# MKW21Z4 register map
Vendor: Freescale Semiconductor, Inc.; Series: Kinetis_W; File version: 1.6
CPU: CM0PLUS r0p0, little endian, no MPU, no FPU, VTOR, 2 interrupt priority bits
Registers are 16-bit, read-write, no defined reset value unless marked. A register's access mark holds for its fields unless they carry their own. Offsets are from the block's base; [hi:lo] are bit positions; {n}, {i} and the like mark numbered series.

## TX_DIG_REGS — XCVR_TX_DIG
Base 0x4005C200
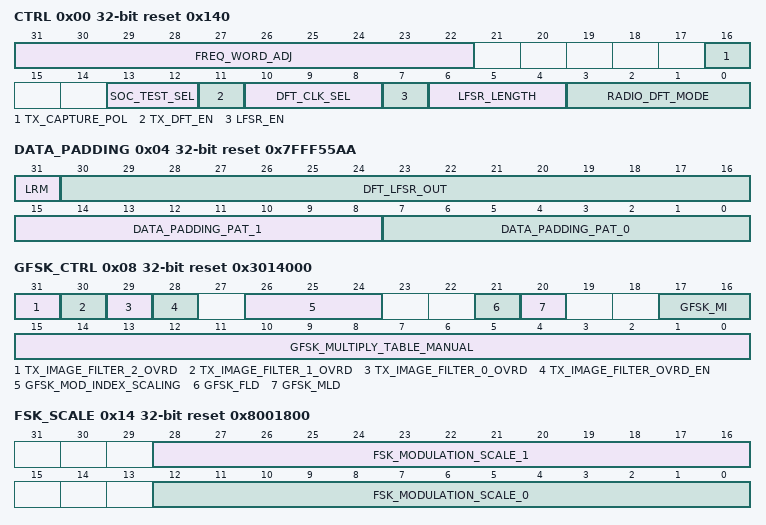
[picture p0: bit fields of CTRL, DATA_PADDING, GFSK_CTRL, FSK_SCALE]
0x00 CTRL 32-bit reset 0x140 — TX Digital Control
  [31:22] FREQ_WORD_ADJ — Frequency Word Adjustment
  [16] TX_CAPTURE_POL — Polarity of the Input Data for the Transmitter
  [13:12] SOC_TEST_SEL — Radio Clock Selector for SoC RF Clock Tests
    0=No Clock Selected; 1=PLL Sigma Delta Clock, divided by 2; 2=Auxiliary PLL Clock, divided by 2; 3=RF Ref Osc clock, divided by 2
  [11] TX_DFT_EN — DFT Modulation Enable
  [10:8] DFT_CLK_SEL — DFT Clock Selection
    0=62.5 kHz; 1=125 kHz; 2=250 kHz; 3=500 kHz; 4=1 MHz; 5=2 MHz; 6=4 MHz; 7=RF OSC Clock
  [7] LFSR_EN — LFSR Enable
  [6:4] LFSR_LENGTH
    0=LFSR 9, tap mask 100010000; 1=LFSR 10, tap mask 1001000000; 2=LFSR 11, tap mask 11101000000; 3=LFSR 13, tap mask 1101100000000; 4=LFSR 15, tap mask 111010000000000; 5=LFSR 17, tap mask 11110000000000000
  [3:0] RADIO_DFT_MODE — Radio DFT Modes
    0=Normal Radio Operation, DFT not engaged; 1=Carrier Frequency Only; 2=Pattern Register GFSK; 3=LFSR GFSK; 4=Pattern Register FSK; 5=LFSR FSK; 6=Pattern Register O-QPSK; 7=LFSR O-QPSK; 8=LFSR 802.15.4 Symbols; 9=PLL Modulation from RAM; 10=PLL Coarse Tune BIST; 11=PLL Frequency Synthesizer BIST; 12=High Port DAC BIST; 13=VCO Frequency Meter
0x04 DATA_PADDING 32-bit reset 0x7FFF55AA — TX Data Padding
  [31] LRM — LFSR Reset Mask
  [30:16] DFT_LFSR_OUT ro — LFSR Output
  [15:8] DATA_PADDING_PAT_1 — Data Padding Pattern 1
  [7:0] DATA_PADDING_PAT_0 — Data Padding Pattern 0
0x08 GFSK_CTRL 32-bit reset 0x3014000 — TX GFSK Modulator Control
  [31] TX_IMAGE_FILTER_2_OVRD — TX Image Filter 2 Override Control
  [30] TX_IMAGE_FILTER_1_OVRD — TX Image Filter 1 Override Control
  [29] TX_IMAGE_FILTER_0_OVRD — TX Image Filter 0 Override Control
  [28] TX_IMAGE_FILTER_OVRD_EN — TX Image Filter Override Enable
  [26:24] GFSK_MOD_INDEX_SCALING — GFSK Modulation Index Scaling Factor
    0=1; 1=1 + 1/32; 2=1 + 1/16; 3=1 + 1/8; 4=1 - 1/32; 5=1 - 1/16; 6=1 - 1/8
  [21] GFSK_FLD — Disable GFSK Filter Lookup Table
  [20] GFSK_MLD — Disable GFSK Multiply Lookup Table
  [17:16] GFSK_MI — GFSK Modulation Index
    0=0.32; 1=0.50; 2=0.70; 3=1.00
  [15:0] GFSK_MULTIPLY_TABLE_MANUAL — Manual GFSK Multiply Lookup Table Value
0x0C GFSK_COEFF2 32-bit reset 0xC0630401 — TX GFSK Filter Coefficients 2
  [31:0] GFSK_FILTER_COEFF_MANUAL2 — GFSK Manual Filter Coefficients[63:32]
0x10 GFSK_COEFF1 32-bit reset 0xBB29960D — TX GFSK Filter Coefficients 1
  [31:0] GFSK_FILTER_COEFF_MANUAL1 — GFSK Manual Filter Coefficient [31:0]
0x14 FSK_SCALE 32-bit reset 0x8001800 — TX FSK Modulation Levels
  [28:16] FSK_MODULATION_SCALE_1 — FSK Modulation Scale for a data 1
  [12:0] FSK_MODULATION_SCALE_0 — FSK Modulation Scale for a data 0
0x18 DFT_PATTERN 32-bit reset 0x0 — TX DFT Modulation Pattern
  [31:0] DFT_MOD_PATTERN — DFT Modulation Pattern
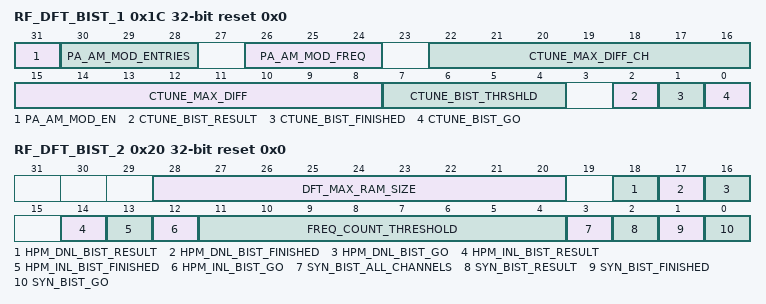
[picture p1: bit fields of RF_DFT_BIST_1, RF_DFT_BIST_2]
0x1C RF_DFT_BIST_1 32-bit reset 0x0 — TX DFT Control 1
  [31] PA_AM_MOD_EN — RF Power Amplifier Amplitude Modulation Enable
  [30:28] PA_AM_MOD_ENTRIES — RF Power Amplifier Amplitude Modulation Table Entries
    {v}={v+1} entries (v=1..7)
  [26:24] PA_AM_MOD_FREQ — RF Power Amplifier Amplitude Modulation Frequency
    0=4 MHz; 1=2 MHz; 2=1 MHz; 3=500 kHz; 4=250 kHz; 5=125 kHz; 6=62.5 kHz
  [22:16] CTUNE_MAX_DIFF_CH ro — Maximum Frequency Count Difference Radio Channel
  [15:8] CTUNE_MAX_DIFF ro — Maximum Frequency Count Difference found by the Coarse Tune BIST
  [7:4] CTUNE_BIST_THRSHLD — Maximum Difference Threshold for Coarse Tune BIST
  [2] CTUNE_BIST_RESULT ro — Coarse Tune BIST Result
  [1] CTUNE_BIST_FINISHED ro — Coarse Tune BIST has finished Tuning all Channels
  [0] CTUNE_BIST_GO — Start the Coarse Tune BIST
0x20 RF_DFT_BIST_2 32-bit reset 0x0 — TX DFT Control 2
  [28:20] DFT_MAX_RAM_SIZE — Maximum RAM Address to use as Modulation
  [18] HPM_DNL_BIST_RESULT ro — High Port Modulator DAC DNL BIST Result
  [17] HPM_DNL_BIST_FINISHED ro — High Port Modulator DAC DNL BIST has finished measuring the DNL of the HPM DAC
  [16] HPM_DNL_BIST_GO — Start the High Port Modulator DAC DNL BIST
  [14] HPM_INL_BIST_RESULT ro — High Port Modulator DAC INL BIST Result
  [13] HPM_INL_BIST_FINISHED ro — High Port Modulator DAC INL BIST has finished measuring the INL of the HPM DAC
  [12] HPM_INL_BIST_GO — Start the High Port Modulator DAC INL BIST
  [11:4] FREQ_COUNT_THRESHOLD — Frequency Meter Count Difference Threshold
  [3] SYN_BIST_ALL_CHANNELS — PLL Frequency Synthesizer BIST All Channels
  [2] SYN_BIST_RESULT ro — PLL Frequency Synthesizer BIST Result
  [1] SYN_BIST_FINISHED ro — PLL Frequency Synthesizer BIST has finished trying to lock to Radio Channels
  [0] SYN_BIST_GO — Start the PLL Frequency Synthesizer BIST
